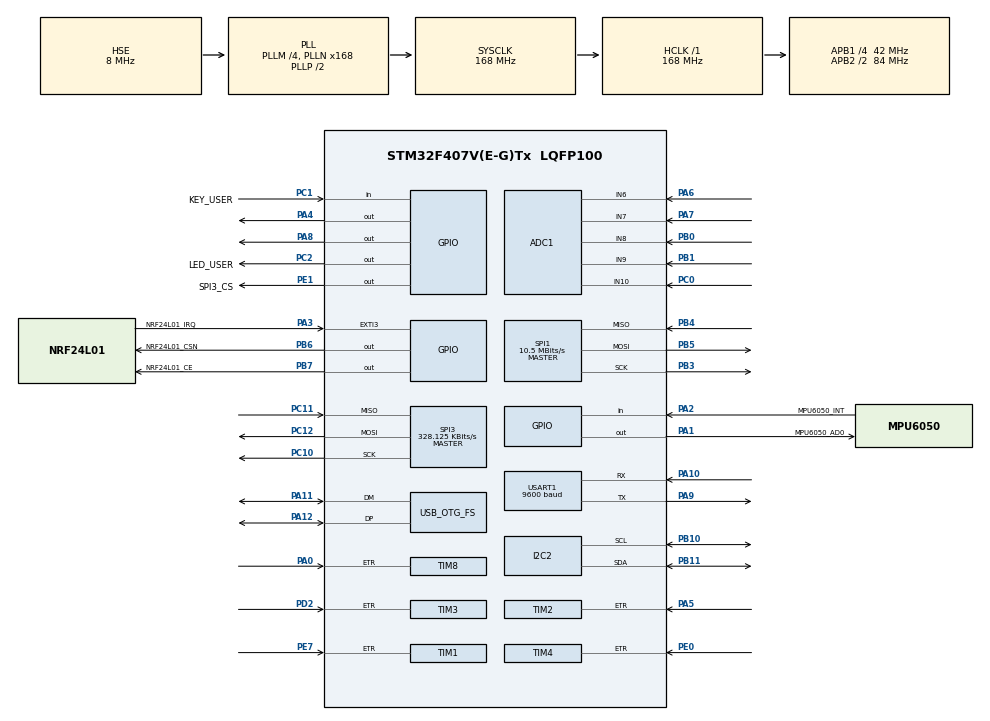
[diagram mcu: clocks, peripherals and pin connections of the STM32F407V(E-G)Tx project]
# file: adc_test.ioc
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ADC1.Channel-17\#ChannelRegularConversion=ADC_CHANNEL_6
ADC1.Channel-18\#ChannelRegularConversion=ADC_CHANNEL_7
ADC1.Channel-19\#ChannelRegularConversion=ADC_CHANNEL_8
ADC1.Channel-20\#ChannelRegularConversion=ADC_CHANNEL_10
ADC1.Channel-21\#ChannelRegularConversion=ADC_CHANNEL_10
ADC1.ContinuousConvMode=ENABLE
ADC1.DMAContinuousRequests=ENABLE
ADC1.NbrOfConversion=5
ADC1.NbrOfConversionFlag=1
ADC1.Rank-17\#ChannelRegularConversion=1
ADC1.Rank-18\#ChannelRegularConversion=2
ADC1.Rank-19\#ChannelRegularConversion=3
ADC1.Rank-20\#ChannelRegularConversion=4
ADC1.Rank-21\#ChannelRegularConversion=5
ADC1.SamplingTime-17\#ChannelRegularConversion=ADC_SAMPLETIME_56CYCLES
ADC1.SamplingTime-18\#ChannelRegularConversion=ADC_SAMPLETIME_56CYCLES
ADC1.SamplingTime-19\#ChannelRegularConversion=ADC_SAMPLETIME_56CYCLES
ADC1.SamplingTime-20\#ChannelRegularConversion=ADC_SAMPLETIME_56CYCLES
ADC1.SamplingTime-21\#ChannelRegularConversion=ADC_SAMPLETIME_56CYCLES
ADC1.ScanConvMode=ENABLE
ADC1.master=1
Dma.ADC1.0.Direction=DMA_PERIPH_TO_MEMORY
Dma.ADC1.0.FIFOMode=DMA_FIFOMODE_DISABLE
Dma.ADC1.0.Instance=DMA2_Stream0
Dma.ADC1.0.MemDataAlignment=DMA_MDATAALIGN_HALFWORD
Dma.ADC1.0.MemInc=DMA_MINC_ENABLE
Dma.ADC1.0.Mode=DMA_CIRCULAR
Dma.ADC1.0.PeriphDataAlignment=DMA_PDATAALIGN_HALFWORD
Dma.ADC1.0.PeriphInc=DMA_PINC_DISABLE
Dma.ADC1.0.Priority=DMA_PRIORITY_LOW
Dma.Request0=ADC1
Dma.Request1=USART1_RX
Dma.Request2=USART1_TX
Dma.USART1_RX.1.Direction=DMA_PERIPH_TO_MEMORY
Dma.USART1_RX.1.FIFOMode=DMA_FIFOMODE_DISABLE
Dma.USART1_RX.1.Instance=DMA2_Stream2
Dma.USART1_RX.1.MemDataAlignment=DMA_MDATAALIGN_BYTE
Dma.USART1_RX.1.MemInc=DMA_MINC_ENABLE
Dma.USART1_RX.1.Mode=DMA_NORMAL
Dma.USART1_RX.1.PeriphDataAlignment=DMA_PDATAALIGN_BYTE
Dma.USART1_RX.1.PeriphInc=DMA_PINC_DISABLE
Dma.USART1_RX.1.Priority=DMA_PRIORITY_MEDIUM
Dma.USART1_TX.2.Direction=DMA_MEMORY_TO_PERIPH
Dma.USART1_TX.2.FIFOMode=DMA_FIFOMODE_DISABLE
Dma.USART1_TX.2.Instance=DMA2_Stream7
Dma.USART1_TX.2.MemDataAlignment=DMA_MDATAALIGN_BYTE
Dma.USART1_TX.2.MemInc=DMA_MINC_ENABLE
Dma.USART1_TX.2.Mode=DMA_NORMAL
Dma.USART1_TX.2.PeriphDataAlignment=DMA_PDATAALIGN_BYTE
Dma.USART1_TX.2.PeriphInc=DMA_PINC_DISABLE
Dma.USART1_TX.2.Priority=DMA_PRIORITY_MEDIUM
I2C2.I2C_Mode=I2C_Standard
Mcu.Family=STM32F4
Mcu.Name=STM32F407V(E-G)Tx
Mcu.Package=LQFP100
NVIC.DMA2_Stream0_IRQn=true\:0\:0\:false\:false\:true\:false\:true\:true
NVIC.DMA2_Stream2_IRQn=true\:0\:0\:false\:false\:true\:false\:true\:true
NVIC.DMA2_Stream7_IRQn=true\:0\:0\:false\:false\:true\:false\:true\:true
NVIC.OTG_FS_IRQn=true\:0\:0\:false\:false\:true\:false\:true\:true
NVIC.PriorityGroup=NVIC_PRIORITYGROUP_4
NVIC.TIM5_IRQn=true\:0\:0\:false\:false\:true\:true\:true\:true
NVIC.USART1_IRQn=true\:0\:0\:false\:false\:true\:true\:true\:true
PA0-WKUP.GPIO_PuPd=GPIO_PULLDOWN
PA0-WKUP.Signal=S_TIM8_ETR
PA1.GPIO_Label=MPU6050_AD0
PA1.GPIO_PuPd=GPIO_PULLDOWN
PA1.Signal=GPIO_Output
PA10.Mode=Asynchronous
PA10.Signal=USART1_RX
PA11.Mode=Device_Only
PA11.Signal=USB_OTG_FS_DM
PA12.Mode=Device_Only
PA12.Signal=USB_OTG_FS_DP
PA13.Mode=Serial_Wire
PA13.Signal=SYS_JTMS-SWDIO
PA14.Mode=Serial_Wire
PA14.Signal=SYS_JTCK-SWCLK
PA2.GPIO_Label=MPU6050_INT
PA2.GPIO_PuPd=GPIO_PULLUP
PA2.Signal=GPIO_Input
PA3.GPIO_Label=NRF24L01_IRQ
PA3.GPIO_ModeDefaultEXTI=GPIO_MODE_IT_FALLING
PA3.GPIO_PuPd=GPIO_PULLUP
PA3.Signal=GPXTI3
PA4.GPIO_PuPd=GPIO_PULLUP
PA4.PinState=GPIO_PIN_SET
PA4.Signal=GPIO_Output
PA5.GPIO_PuPd=GPIO_PULLDOWN
PA5.Signal=S_TIM2_CH1_ETR
PA6.Signal=ADCx_IN6
PA7.Signal=ADCx_IN7
PA8.GPIO_PuPd=GPIO_PULLDOWN
PA8.Signal=GPIO_Output
PA9.Mode=Asynchronous
PA9.Signal=USART1_TX
PB0.Signal=ADCx_IN8
PB1.Signal=ADCx_IN9
PB10.Mode=I2C
PB10.Signal=I2C2_SCL
PB11.Mode=I2C
PB11.Signal=I2C2_SDA
PB3.Mode=Full_Duplex_Master
PB3.Signal=SPI1_SCK
PB4.Mode=Full_Duplex_Master
PB4.Signal=SPI1_MISO
PB5.Mode=Full_Duplex_Master
PB5.Signal=SPI1_MOSI
PB6.GPIO_Label=NRF24L01_CSN
PB6.Signal=GPIO_Output
PB7.GPIO_Label=NRF24L01_CE
PB7.Signal=GPIO_Output
PC0.Signal=ADCx_IN10
PC1.GPIO_Label=KEY_USER
PC1.GPIO_PuPd=GPIO_PULLUP
PC1.Signal=GPIO_Input
PC10.Mode=Full_Duplex_Master
PC10.Signal=SPI3_SCK
PC11.Mode=Full_Duplex_Master
PC11.Signal=SPI3_MISO
PC12.Mode=Full_Duplex_Master
PC12.Signal=SPI3_MOSI
PC2.GPIO_Label=LED_USER
PC2.GPIO_PuPd=GPIO_PULLUP
PC2.PinState=GPIO_PIN_SET
PC2.Signal=GPIO_Output
PD2.GPIO_PuPd=GPIO_PULLDOWN
PD2.Signal=S_TIM3_ETR
PE0.GPIO_PuPd=GPIO_PULLDOWN
PE0.Signal=S_TIM4_ETR
PE1.GPIO_Label=SPI3_CS
PE1.Signal=GPIO_Output
PE7.GPIO_PuPd=GPIO_PULLDOWN
PE7.Signal=S_TIM1_ETR
PH0-OSC_IN.Mode=HSE-External-Oscillator
PH0-OSC_IN.Signal=RCC_OSC_IN
PH1-OSC_OUT.Mode=HSE-External-Oscillator
PH1-OSC_OUT.Signal=RCC_OSC_OUT
ProjectManager.HeapSize=0x200
ProjectManager.StackSize=0x400
ProjectManager.TargetToolchain=MDK-ARM V5.32
RCC.48MHZClocksFreq_Value=48000000
RCC.AHBFreq_Value=168000000
RCC.APB1CLKDivider=RCC_HCLK_DIV4
RCC.APB1Freq_Value=42000000
RCC.APB1TimFreq_Value=84000000
RCC.APB2CLKDivider=RCC_HCLK_DIV2
RCC.APB2Freq_Value=84000000
RCC.APB2TimFreq_Value=168000000
RCC.CortexFreq_Value=168000000
RCC.HCLKFreq_Value=168000000
RCC.HSE_VALUE=8000000
RCC.HSI_VALUE=16000000
RCC.LSE_VALUE=32768
RCC.PLLM=4
RCC.PLLN=168
RCC.PLLQ=7
RCC.SYSCLKFreq_VALUE=168000000
RCC.SYSCLKSource=RCC_SYSCLKSOURCE_PLLCLK
RCC.VCOOutputFreq_Value=336000000
SH.ADCx_IN10.0=ADC1_IN10,IN10
SH.ADCx_IN6.0=ADC1_IN6,IN6
SH.ADCx_IN7.0=ADC1_IN7,IN7
SH.ADCx_IN8.0=ADC1_IN8,IN8
SH.ADCx_IN9.0=ADC1_IN9,IN9
SH.S_TIM1_ETR.0=TIM1_ETR,ClockSourceETR_Mode2
SH.S_TIM2_CH1_ETR.0=TIM2_ETR,ClockSourceETR_Mode2
SH.S_TIM3_ETR.0=TIM3_ETR,ClockSourceETR_Mode2
SH.S_TIM4_ETR.0=TIM4_ETR,ClockSourceETR_Mode2
SH.S_TIM8_ETR.0=TIM8_ETR,ClockSourceETR_Mode2
SPI1.BaudRatePrescaler=SPI_BAUDRATEPRESCALER_8
SPI1.CalculateBaudRate=10.5 MBits/s
SPI1.Direction=SPI_DIRECTION_2LINES
SPI1.Mode=SPI_MODE_MASTER
SPI1.VirtualType=VM_MASTER
SPI3.BaudRatePrescaler=SPI_BAUDRATEPRESCALER_128
SPI3.CLKPhase=SPI_PHASE_2EDGE
SPI3.CLKPolarity=SPI_POLARITY_HIGH
SPI3.CalculateBaudRate=328.125 KBits/s
SPI3.Direction=SPI_DIRECTION_2LINES
SPI3.Mode=SPI_MODE_MASTER
SPI3.VirtualType=VM_MASTER
TIM2.Period=65535
TIM5.Period=999
TIM5.Prescaler=8399
USART1.BaudRate=9600
USART1.VirtualMode=VM_ASYNC
USB_DEVICE.CLASS_NAME_FS=CDC
USB_DEVICE.VirtualMode-CDC_FS=Cdc
USB_DEVICE.VirtualModeFS=Cdc_FS
USB_OTG_FS.VirtualMode=Device_Only
VP_TIM5_VS_ClockSourceINT.Mode=Internal
VP_USB_DEVICE_VS_USB_DEVICE_CDC_FS.Mode=CDC_FS
board=custom

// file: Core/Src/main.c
/* USER CODE BEGIN Header */
/**
  ******************************************************************************
  * @file           : main.c
  * @brief          : Main program body
  ******************************************************************************
  * @attention
  *
  * Copyright (c) 2024 STMicroelectronics.
  * All rights reserved.
  *
  * This software is licensed under terms that can be found in the LICENSE file
  * in the root directory of this software component.
  * If no LICENSE file comes with this software, it is provided AS-IS.
  *
  ******************************************************************************
  */
/* USER CODE END Header */
#include "main.h"
#include "adc.h"
#include "dma.h"
#include "i2c.h"
#include "spi.h"
#include "tim.h"
#include "usart.h"
#include "usb_device.h"
#include "gpio.h"

/* USER CODE BEGIN Includes */
#include "bringup.h"
/* USER CODE END Includes */

void SystemClock_Config(void);

int main(void)
{

  /* MCU Configuration--------------------------------------------------------*/

  /* Reset of all peripherals, Initializes the Flash interface and the Systick. */
  HAL_Init();

  /* Configure the system clock */
  SystemClock_Config();

  /* Initialize all configured peripherals */
  MX_GPIO_Init();
  MX_DMA_Init();
  MX_TIM3_Init();
  MX_USB_DEVICE_Init();
  MX_I2C2_Init();
  MX_USART1_UART_Init();
  MX_ADC1_Init();
  MX_TIM2_Init();
  MX_TIM1_Init();
  MX_TIM4_Init();
  MX_TIM5_Init();
  MX_TIM8_Init();
  MX_SPI3_Init();
  MX_SPI1_Init();
  /* USER CODE BEGIN 2 */
	bringup_init();
  /* USER CODE END 2 */

  /* Infinite loop */
  while (1)
  {

    /* USER CODE BEGIN 3 */
		main_loop();
  }
  /* USER CODE END 3 */
}

void SystemClock_Config(void)
{
  RCC_OscInitTypeDef RCC_OscInitStruct = {0};
  RCC_ClkInitTypeDef RCC_ClkInitStruct = {0};

  /** Configure the main internal regulator output voltage
  */
  __HAL_RCC_PWR_CLK_ENABLE();
  __HAL_PWR_VOLTAGESCALING_CONFIG(PWR_REGULATOR_VOLTAGE_SCALE1);

  /** Initializes the RCC Oscillators according to the specified parameters
  * in the RCC_OscInitTypeDef structure.
  */
  RCC_OscInitStruct.OscillatorType = RCC_OSCILLATORTYPE_HSE;
  RCC_OscInitStruct.HSEState = RCC_HSE_ON;
  RCC_OscInitStruct.PLL.PLLState = RCC_PLL_ON;
  RCC_OscInitStruct.PLL.PLLSource = RCC_PLLSOURCE_HSE;
  RCC_OscInitStruct.PLL.PLLM = 4;
  RCC_OscInitStruct.PLL.PLLN = 168;
  RCC_OscInitStruct.PLL.PLLP = RCC_PLLP_DIV2;
  RCC_OscInitStruct.PLL.PLLQ = 7;
  if (HAL_RCC_OscConfig(&RCC_OscInitStruct) != HAL_OK)
  {
    Error_Handler();
  }

  /** Initializes the CPU, AHB and APB buses clocks
  */
  RCC_ClkInitStruct.ClockType = RCC_CLOCKTYPE_HCLK|RCC_CLOCKTYPE_SYSCLK
                              |RCC_CLOCKTYPE_PCLK1|RCC_CLOCKTYPE_PCLK2;
  RCC_ClkInitStruct.SYSCLKSource = RCC_SYSCLKSOURCE_PLLCLK;
  RCC_ClkInitStruct.AHBCLKDivider = RCC_SYSCLK_DIV1;
  RCC_ClkInitStruct.APB1CLKDivider = RCC_HCLK_DIV4;
  RCC_ClkInitStruct.APB2CLKDivider = RCC_HCLK_DIV2;

  if (HAL_RCC_ClockConfig(&RCC_ClkInitStruct, FLASH_LATENCY_5) != HAL_OK)
  {
    Error_Handler();
  }
}

void Error_Handler(void)
{
  __disable_irq();
  while (1)
  {
  }
}
